# WLR089U0 register map
Vendor: Microchip
Registers are 32-bit, read-write, reset 0x0 unless marked. A register's access mark holds for its fields unless they carry their own. Addresses are absolute, and some are shared; only a register's first bit layout is shown; [hi:lo] are bit positions; {n}, {i} and the like mark numbered series; 'fields as' and 'values as' point back to an identical list.

## PM
0x40000000 CTRLA 8-bit
  [2] IORET — I/O Retention
0x40000001 SLEEPCFG 8-bit reset 0x2
  [2:0] SLEEPMODE
    2=IDLE (CPU, AHBx, and APBx clocks are OFF); 4=STANDBY (All Clocks are OFF); 5=BACKUP (Only Backup domain is powered ON); 6=OFF (All power domains are powered OFF)
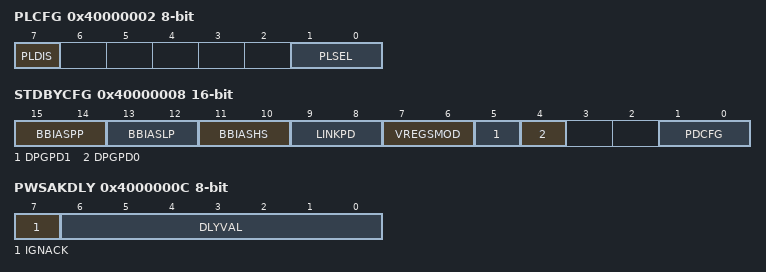
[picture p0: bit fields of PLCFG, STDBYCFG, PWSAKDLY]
0x40000002 PLCFG 8-bit
  [7] PLDIS — Performance Level Disable
  [1:0] PLSEL — Performance Level Select
    0=PL0 (Performance Level 0); 1=PL1 (Performance Level 1); 2=PL2 (Performance Level 2)
0x40000004 INTENCLR 8-bit
  [0] PLRDY — Performance Level Interrupt Enable
0x40000005 INTENSET 8-bit
  [0] PLRDY — Performance Level Ready interrupt Enable
0x40000006 INTFLAG 8-bit
  [0] PLRDY — Performance Level Ready
0x40000008 STDBYCFG 16-bit
  [15:14] BBIASPP — Back Bias for PicoPram
  [13:12] BBIASLP — Back Bias for HMCRAMCLP
  [11:10] BBIASHS — Back Bias for HMCRAMCHS
  [9:8] LINKPD — Linked Power Domain
    0=DEFAULT (Power domains are not linked); 1=PD01 (PD0 and PD1 power domains are linked); 2=PD12 (PD1 and PD2 power domains are linked); 3=PD012 (All power domains are linked)
  [7:6] VREGSMOD — Voltage Regulator Standby mode
    0=AUTO (Automatic mode); 1=PERFORMANCE (Performance oriented); 2=LP (Low Power oriented)
  [5] DPGPD1 — Dynamic Power Gating for PD1
  [4] DPGPD0 — Dynamic Power Gating for PD0
  [1:0] PDCFG — Power Domain Configuration
    0=DEFAULT (All power domains switching is handled by hardware.); 1=PD0 (PD0 is forced ACTIVE. PD1 and PD2 power domains switching is handled by hardware.); 2=PD01 (PD0 and PD1 are forced ACTIVE. PD2 power domain switching is handled by hardware.); 3=PD012 (All power domains are forced ACTIVE.)
0x4000000C PWSAKDLY 8-bit
  [7] IGNACK — Ignore Acknowledge
  [6:0] DLYVAL — Delay Value

## MCLK
0x40000400 CTRLA 8-bit
0x40000401 INTENCLR 8-bit
  [0] CKRDY — Clock Ready Interrupt Enable
0x40000402 INTENSET 8-bit
  [0] CKRDY — Clock Ready Interrupt Enable
0x40000403 INTFLAG 8-bit reset 0x1
  [0] CKRDY — Clock Ready
0x40000404 CPUDIV 8-bit reset 0x1
  [7:0] CPUDIV — CPU Clock Division Factor
    1=DIV1 (Divide by 1); 2=DIV2 (Divide by 2); 4=DIV4 (Divide by 4); 8=DIV8 (Divide by 8); 16=DIV16 (Divide by 16); 32=DIV32 (Divide by 32); 64=DIV64 (Divide by 64); 128=DIV128 (Divide by 128)
0x40000405 LPDIV 8-bit reset 0x1
  [7:0] LPDIV — Low-Power Clock Division Factor
    values as CPUDIV.CPUDIV
0x40000406 BUPDIV 8-bit reset 0x1
  [7:0] BUPDIV — Backup Clock Division Factor
    values as CPUDIV.CPUDIV
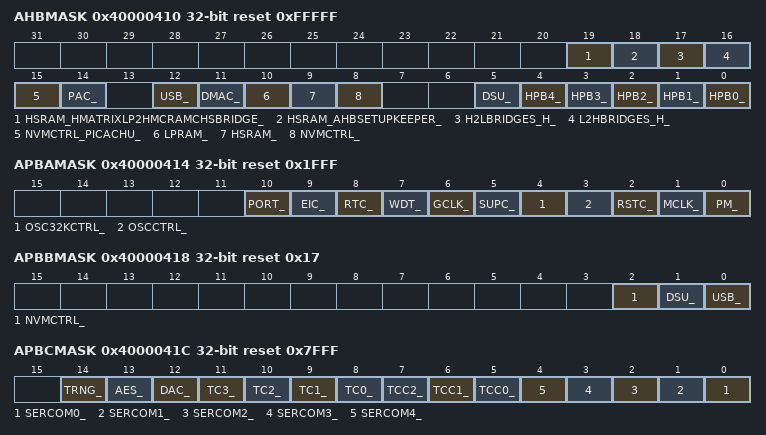
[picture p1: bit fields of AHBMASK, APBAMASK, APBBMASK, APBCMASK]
0x40000410 AHBMASK reset 0xFFFFF
  [19] HSRAM_HMATRIXLP2HMCRAMCHSBRIDGE_ — HSRAM_HMATRIXLP2HMCRAMCHSBRIDGE AHB Clock Mask
  [18] HSRAM_AHBSETUPKEEPER_ — HSRAM_AHBSETUPKEEPER AHB Clock Mask
  [17] H2LBRIDGES_H_ — H2LBRIDGES_H AHB Clock Mask
  [16] L2HBRIDGES_H_ — L2HBRIDGES_H AHB Clock Mask
  [15] NVMCTRL_PICACHU_ — NVMCTRL_PICACHU AHB Clock Mask
  [14] PAC_ — PAC AHB Clock Mask
  [12] USB_ — USB AHB Clock Mask
  [11] DMAC_ — DMAC AHB Clock Mask
  [10] LPRAM_ — LPRAM AHB Clock Mask
  [9] HSRAM_ — HSRAM AHB Clock Mask
  [8] NVMCTRL_ — NVMCTRL AHB Clock Mask
  [5] DSU_ — DSU AHB Clock Mask
  [n] HPB{n}_ (n=0..4) — HPB{n} AHB Clock Mask
0x40000414 APBAMASK reset 0x1FFF
  [10] PORT_ — PORT APB Clock Enable
  [9] EIC_ — EIC APB Clock Enable
  [8] RTC_ — RTC APB Clock Enable
  [7] WDT_ — WDT APB Clock Enable
  [6] GCLK_ — GCLK APB Clock Enable
  [5] SUPC_ — SUPC APB Clock Enable
  [4] OSC32KCTRL_ — OSC32KCTRL APB Clock Enable
  [3] OSCCTRL_ — OSCCTRL APB Clock Enable
  [2] RSTC_ — RSTC APB Clock Enable
  [1] MCLK_ — MCLK APB Clock Enable
  [0] PM_ — PM APB Clock Enable
0x40000418 APBBMASK reset 0x17
  [2] NVMCTRL_ — NVMCTRL APB Clock Enable
  [1] DSU_ — DSU APB Clock Enable
  [0] USB_ — USB APB Clock Enable
0x4000041C APBCMASK reset 0x7FFF
  [14] TRNG_ — TRNG APB Clock Enable
  [13] AES_ — AES APB Clock Enable
  [12] DAC_ — DAC APB Clock Enable
  [n+8] TC{n}_ (n=0..3) — TC{n} APB Clock Enable
  [7] TCC2_ — TCC2 APB Clock Enable
  [6] TCC1_ — TCC1 APB Clock Enable
  [5] TCC0_ — TCC0 APB Clock Enable
  [n] SERCOM{n}_ (n=0..4) — SERCOM{n} APB Clock Enable
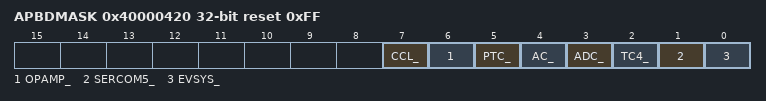
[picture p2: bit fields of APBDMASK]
0x40000420 APBDMASK reset 0xFF
  [7] CCL_ — CCL APB Clock Enable
  [6] OPAMP_ — OPAMP APB Clock Enable
  [5] PTC_ — PTC APB Clock Enable
  [4] AC_ — AC APB Clock Enable
  [3] ADC_ — ADC APB Clock Enable
  [2] TC4_ — TC4 APB Clock Enable
  [1] SERCOM5_ — SERCOM5 APB Clock Enable
  [0] EVSYS_ — EVSYS APB Clock Enable
0x40000424 APBEMASK reset 0xD
  [0] PAC_ — PAC APB Clock Enable
